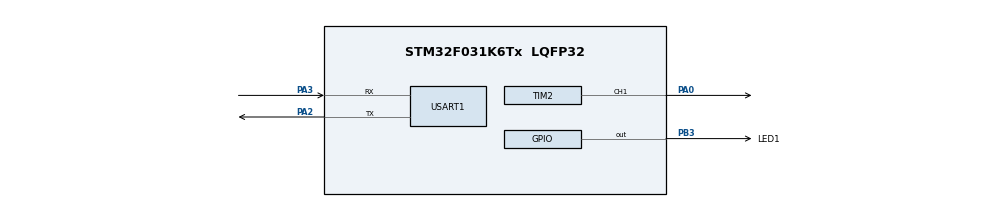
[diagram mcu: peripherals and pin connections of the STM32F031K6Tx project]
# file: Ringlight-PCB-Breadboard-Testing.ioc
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Mcu.Family=STM32F0
Mcu.Name=STM32F031K6Tx
Mcu.Package=LQFP32
PA0.Signal=S_TIM2_CH1_ETR
PA13.Mode=Serial_Wire
PA13.Signal=SYS_SWDIO
PA14.Mode=Serial_Wire
PA14.Signal=SYS_SWCLK
PA2.Mode=Asynchronous
PA2.Signal=USART1_TX
PA3.Mode=Asynchronous
PA3.Signal=USART1_RX
PB3.GPIO_Label=LED1
PB3.Signal=GPIO_Output
ProjectManager.HeapSize=0x200
ProjectManager.StackSize=0x400
ProjectManager.TargetToolchain=STM32CubeIDE
SH.S_TIM2_CH1_ETR.0=TIM2_CH1,PWM Generation1 CH1
TIM2.Channel-PWM\ Generation1\ CH1=TIM_CHANNEL_1
TIM2.Period=255
TIM2.Prescaler=8-1
TIM2.Pulse-PWM\ Generation1\ CH1=255
USART1.VirtualMode-Asynchronous=VM_ASYNC
VP_TIM2_VS_ClockSourceINT.Mode=Internal
board=custom

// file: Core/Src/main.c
/* USER CODE BEGIN Header */
/**
  ******************************************************************************
  * @file           : main.c
  * @brief          : Main program body
  ******************************************************************************
  * @attention
  *
  * Copyright (c) 2025 STMicroelectronics.
  * All rights reserved.
  *
  * This software is licensed under terms that can be found in the LICENSE file
  * in the root directory of this software component.
  * If no LICENSE file comes with this software, it is provided AS-IS.
  *
  ******************************************************************************
  */
/* USER CODE END Header */
#include "main.h"

TIM_HandleTypeDef htim2;

UART_HandleTypeDef huart1;

void SystemClock_Config(void);
static void MX_GPIO_Init(void);
static void MX_USART1_UART_Init(void);
static void MX_TIM2_Init(void);

int main(void)
{

  /* MCU Configuration--------------------------------------------------------*/

  /* Reset of all peripherals, Initializes the Flash interface and the Systick. */
  HAL_Init();

  /* Configure the system clock */
  SystemClock_Config();

  /* Initialize all configured peripherals */
  MX_GPIO_Init();
  MX_USART1_UART_Init();
  MX_TIM2_Init();
  /* USER CODE BEGIN 2 */

  HAL_TIM_PWM_Start(&htim2, TIM_CHANNEL_1);

  // change the duty cycle to 50%

  /* USER CODE END 2 */

  /* Infinite loop */
  /* USER CODE BEGIN WHILE */
  int iters = 0;
  while (1)
  {
    /* USER CODE END WHILE */

    /* USER CODE BEGIN 3 */

    HAL_GPIO_TogglePin(LED1_GPIO_Port, LED1_Pin);
    HAL_Delay(100);
    __HAL_TIM_SET_COMPARE(&htim2, TIM_CHANNEL_1, iters);
    iters += 5;
    if (iters >= 255) {
      iters = 0;
    }
  }
  /* USER CODE END 3 */
}

void SystemClock_Config(void)
{
  RCC_OscInitTypeDef RCC_OscInitStruct = {0};
  RCC_ClkInitTypeDef RCC_ClkInitStruct = {0};
  RCC_PeriphCLKInitTypeDef PeriphClkInit = {0};

  /** Initializes the RCC Oscillators according to the specified parameters
  * in the RCC_OscInitTypeDef structure.
  */
  RCC_OscInitStruct.OscillatorType = RCC_OSCILLATORTYPE_HSI;
  RCC_OscInitStruct.HSIState = RCC_HSI_ON;
  RCC_OscInitStruct.HSICalibrationValue = RCC_HSICALIBRATION_DEFAULT;
  RCC_OscInitStruct.PLL.PLLState = RCC_PLL_NONE;
  if (HAL_RCC_OscConfig(&RCC_OscInitStruct) != HAL_OK)
  {
    Error_Handler();
  }

  /** Initializes the CPU, AHB and APB buses clocks
  */
  RCC_ClkInitStruct.ClockType = RCC_CLOCKTYPE_HCLK|RCC_CLOCKTYPE_SYSCLK
                              |RCC_CLOCKTYPE_PCLK1;
  RCC_ClkInitStruct.SYSCLKSource = RCC_SYSCLKSOURCE_HSI;
  RCC_ClkInitStruct.AHBCLKDivider = RCC_SYSCLK_DIV1;
  RCC_ClkInitStruct.APB1CLKDivider = RCC_HCLK_DIV1;

  if (HAL_RCC_ClockConfig(&RCC_ClkInitStruct, FLASH_LATENCY_0) != HAL_OK)
  {
    Error_Handler();
  }
  PeriphClkInit.PeriphClockSelection = RCC_PERIPHCLK_USART1;
  PeriphClkInit.Usart1ClockSelection = RCC_USART1CLKSOURCE_PCLK1;
  if (HAL_RCCEx_PeriphCLKConfig(&PeriphClkInit) != HAL_OK)
  {
    Error_Handler();
  }
}

static void MX_TIM2_Init(void)
{

  TIM_ClockConfigTypeDef sClockSourceConfig = {0};
  TIM_MasterConfigTypeDef sMasterConfig = {0};
  TIM_OC_InitTypeDef sConfigOC = {0};

  htim2.Instance = TIM2;
  htim2.Init.Prescaler = 8-1;
  htim2.Init.CounterMode = TIM_COUNTERMODE_UP;
  htim2.Init.Period = 255;
  htim2.Init.ClockDivision = TIM_CLOCKDIVISION_DIV1;
  htim2.Init.AutoReloadPreload = TIM_AUTORELOAD_PRELOAD_DISABLE;
  if (HAL_TIM_Base_Init(&htim2) != HAL_OK)
  {
    Error_Handler();
  }
  sClockSourceConfig.ClockSource = TIM_CLOCKSOURCE_INTERNAL;
  if (HAL_TIM_ConfigClockSource(&htim2, &sClockSourceConfig) != HAL_OK)
  {
    Error_Handler();
  }
  if (HAL_TIM_PWM_Init(&htim2) != HAL_OK)
  {
    Error_Handler();
  }
  sMasterConfig.MasterOutputTrigger = TIM_TRGO_RESET;
  sMasterConfig.MasterSlaveMode = TIM_MASTERSLAVEMODE_DISABLE;
  if (HAL_TIMEx_MasterConfigSynchronization(&htim2, &sMasterConfig) != HAL_OK)
  {
    Error_Handler();
  }
  sConfigOC.OCMode = TIM_OCMODE_PWM1;
  sConfigOC.Pulse = 255;
  sConfigOC.OCPolarity = TIM_OCPOLARITY_HIGH;
  sConfigOC.OCFastMode = TIM_OCFAST_DISABLE;
  if (HAL_TIM_PWM_ConfigChannel(&htim2, &sConfigOC, TIM_CHANNEL_1) != HAL_OK)
  {
    Error_Handler();
  }
  HAL_TIM_MspPostInit(&htim2);

}

static void MX_USART1_UART_Init(void)
{

  huart1.Instance = USART1;
  huart1.Init.BaudRate = 38400;
  huart1.Init.WordLength = UART_WORDLENGTH_8B;
  huart1.Init.StopBits = UART_STOPBITS_1;
  huart1.Init.Parity = UART_PARITY_NONE;
  huart1.Init.Mode = UART_MODE_TX_RX;
  huart1.Init.HwFlowCtl = UART_HWCONTROL_NONE;
  huart1.Init.OverSampling = UART_OVERSAMPLING_16;
  huart1.Init.OneBitSampling = UART_ONE_BIT_SAMPLE_DISABLE;
  huart1.AdvancedInit.AdvFeatureInit = UART_ADVFEATURE_NO_INIT;
  if (HAL_UART_Init(&huart1) != HAL_OK)
  {
    Error_Handler();
  }

}

static void MX_GPIO_Init(void)
{
  GPIO_InitTypeDef GPIO_InitStruct = {0};

  /* GPIO Ports Clock Enable */
  __HAL_RCC_GPIOA_CLK_ENABLE();
  __HAL_RCC_GPIOB_CLK_ENABLE();

  /*Configure GPIO pin Output Level */
  HAL_GPIO_WritePin(LED1_GPIO_Port, LED1_Pin, GPIO_PIN_RESET);

  /*Configure GPIO pin : LED1_Pin */
  GPIO_InitStruct.Pin = LED1_Pin;
  GPIO_InitStruct.Mode = GPIO_MODE_OUTPUT_PP;
  GPIO_InitStruct.Pull = GPIO_NOPULL;
  GPIO_InitStruct.Speed = GPIO_SPEED_FREQ_LOW;
  HAL_GPIO_Init(LED1_GPIO_Port, &GPIO_InitStruct);

}

void Error_Handler(void)
{
  __disable_irq();
  while (1)
  {
  }
}
